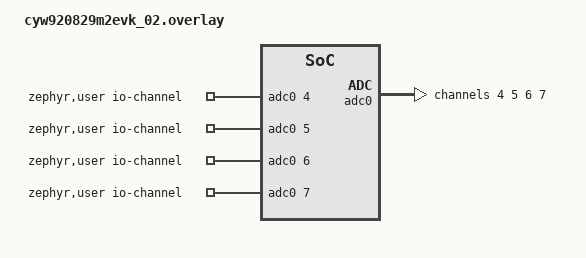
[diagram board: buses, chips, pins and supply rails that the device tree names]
/*
 * SPDX-License-Identifier: Apache-2.0
 *
 * Copyright (c) 2023 Cypress Semiconductor Corporation (an Infineon company) or
 * an affiliate of Cypress Semiconductor Corporation
 */

#include <zephyr/dt-bindings/adc/adc.h>

/ {
	zephyr,user {
		io-channels = <&adc0 4>, <&adc0 5>, <&adc0 6>, <&adc0 7>;
	};
};

&adc0 {
	status = "okay";
	#address-cells = <1>;
	#size-cells = <0>;

	channel@4 {
		reg = <4>;
		zephyr,acquisition-time = <ADC_ACQ_TIME(ADC_ACQ_TIME_MICROSECONDS, 1)>;
		zephyr,gain = "ADC_GAIN_1";
		zephyr,reference = "ADC_REF_INTERNAL";
		zephyr,resolution = <16>;
		zephyr,input-positive = <4>;   /* P3.4 */
	};

	channel@5 {
		reg = <5>;
		zephyr,acquisition-time = <ADC_ACQ_TIME(ADC_ACQ_TIME_MICROSECONDS, 1)>;
		zephyr,gain = "ADC_GAIN_1";
		zephyr,reference = "ADC_REF_INTERNAL";
		zephyr,resolution = <16>;
		zephyr,input-positive = <5>;   /* P3.5 */
	};

	channel@6 {
		reg = <6>;
		zephyr,acquisition-time = <ADC_ACQ_TIME(ADC_ACQ_TIME_MICROSECONDS, 1)>;
		zephyr,gain = "ADC_GAIN_1";
		zephyr,reference = "ADC_REF_INTERNAL";
		zephyr,resolution = <16>;
		zephyr,input-positive = <6>;   /* P3.6 */
	};

	channel@7 {
		reg = <7>;
		zephyr,acquisition-time = <ADC_ACQ_TIME(ADC_ACQ_TIME_MICROSECONDS, 1)>;
		zephyr,gain = "ADC_GAIN_1";
		zephyr,reference = "ADC_REF_INTERNAL";
		zephyr,resolution = <16>;
		zephyr,input-positive = <7>;   /* P3.7 */
	};
};
